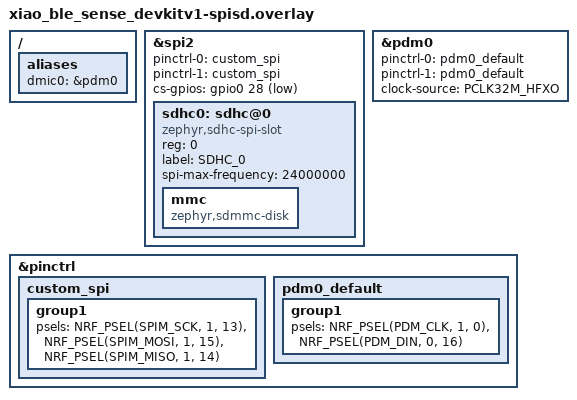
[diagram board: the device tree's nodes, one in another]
/ {
    aliases {
        dmic0 = &pdm0;
    };
};

&spi2 {
    status = "okay";
    pinctrl-0 = <&custom_spi>;
    pinctrl-1 = <&custom_spi>;
    pinctrl-names = "default", "sleep";
    cs-gpios = <&gpio0 28 GPIO_ACTIVE_LOW>;  // CS pin on P0.28
    sdhc0: sdhc@0 {
        compatible = "zephyr,sdhc-spi-slot";
        reg = <0>;
        status = "okay";
        label = "SDHC_0";
        mmc {
            compatible = "zephyr,sdmmc-disk";
            status = "okay";
        };
        spi-max-frequency = <24000000>;  // 24 MHz SPI speed for SD card
    };
};

&pdm0 {
    status = "okay";
    pinctrl-0 = <&pdm0_default>;
    pinctrl-1 = <&pdm0_default>;
    pinctrl-names = "default", "sleep";
    clock-source = "PCLK32M_HFXO";
};

&pinctrl {
    custom_spi: custom_spi {
        group1 {
            psels = <NRF_PSEL(SPIM_SCK, 1, 13)>,  // SCK on P1.13
                    <NRF_PSEL(SPIM_MOSI, 1, 15)>, // MOSI on P1.15
                    <NRF_PSEL(SPIM_MISO, 1, 14)>; // MISO on P1.14
        };
    };

    pdm0_default: pdm0_default {
        group1 {
            psels = <NRF_PSEL(PDM_CLK, 1, 0)>,   // PDM CLK on P1.00
                    <NRF_PSEL(PDM_DIN, 0, 16)>;  // PDM DIN on P0.16
        };
    };
};
